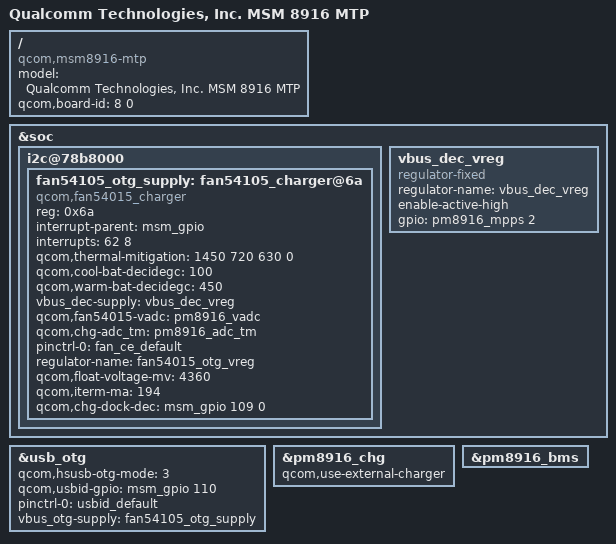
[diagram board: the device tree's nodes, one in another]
/* Copyright (c) 2014, The Linux Foundation. All rights reserved.
*
* This program is free software; you can redistribute it and/or modify
* it under the terms of the GNU General Public License version 2 and
* only version 2 as published by the Free Software Foundation.
*
* This program is distributed in the hope that it will be useful,
* but WITHOUT ANY WARRANTY; without even the implied warranty of
* MERCHANTABILITY or FITNESS FOR A PARTICULAR PURPOSE.  See the
* GNU General Public License for more details.
*/

/dts-v1/;

#include "msm8916-mtp.dtsi"
#include "msm8916-memory.dtsi"

/ {
	model = "Qualcomm Technologies, Inc. MSM 8916 MTP";
	compatible = "qcom,msm8916-mtp", "qcom,msm8916", "qcom,mtp";
	qcom,board-id = <8 0>;
};
//[PLATFORM]Add BEGIN by TCTSZ-Leo.guo 2014/10/09, add for fan54015 charger IC & usb otg function.
&soc {
	i2c@78b8000 {
        fan54105_otg_supply: fan54105_charger@6a {
            compatible = "qcom,fan54015_charger";
            reg = <0x6a>;
			interrupt-parent = <&msm_gpio>;
			interrupts = <62 8>;

			qcom,thermal-mitigation = <1450 720 630 0>;
			qcom,cool-bat-decidegc = <100>;
			qcom,warm-bat-decidegc = <450>;

			vbus_dec-supply = <&vbus_dec_vreg>;
			qcom,fan54015-vadc = <&pm8916_vadc>;
			qcom,chg-adc_tm = <&pm8916_adc_tm>;
			pinctrl-names = "default";
			pinctrl-0 = <&fan_ce_default>;
			regulator-name = "fan54015_otg_vreg";

			qcom,float-voltage-mv = <4360>;
			qcom,iterm-ma = <194>;

			qcom,chg-dock-dec = <&msm_gpio 109 0>;
		};
	};

	vbus_dec_vreg: vbus_dec_vreg {
		compatible = "regulator-fixed";
		regulator-name = "vbus_dec_vreg";
		enable-active-high;
		gpio = <&pm8916_mpps 2 0>;
	};
};


&usb_otg {
	qcom,hsusb-otg-mode = <3>;
	qcom,usbid-gpio = <&msm_gpio 110 0>;
	pinctrl-names = "default";
	pinctrl-0 = <&usbid_default>;
	vbus_otg-supply = <&fan54105_otg_supply>;
};


&pm8916_chg {
	status = "ok";
	qcom,use-external-charger;
};

&pm8916_bms {
	status = "ok";
};
//[PLATFORM]Add END by TCTSZ-Leo.guo 2014/10/09.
